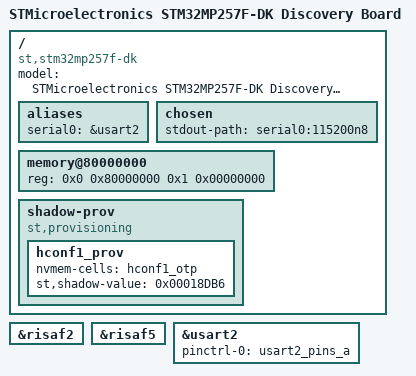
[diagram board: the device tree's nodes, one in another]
// SPDX-License-Identifier: (GPL-2.0-or-later OR BSD-3-Clause)
/*
 * Copyright (C) STMicroelectronics 2023 - All Rights Reserved
 * Author: Alexandre Torgue <alexandre.torgue@foss.st.com> for STMicroelectronics.
 */

/dts-v1/;

#include <dt-bindings/soc/stm32mp-provisioning.h>
#include "stm32mp257.dtsi"
#include "stm32mp25xf.dtsi"
#include "stm32mp25-pinctrl.dtsi"
#include "stm32mp25xxal-pinctrl.dtsi"

/ {
	model = "STMicroelectronics STM32MP257F-DK Discovery Board";
	compatible = "st,stm32mp257f-dk", "st,stm32mp257";

	aliases {
		serial0 = &usart2;
	};

	chosen {
		stdout-path = "serial0:115200n8";
	};

	memory@80000000 {
		device_type = "memory";
		reg = <0x0 0x80000000 0x1 0x00000000>;
	};

	shadow-prov {
		compatible = "st,provisioning";
		hconf1_prov {
			nvmem-cells = <&hconf1_otp>;
			st,shadow-value = <0x00018DB6>;
		};
	};
};

&risaf2 {
	status = "okay";
};

&risaf5 {
	status = "okay";
};

&usart2 {
	pinctrl-names = "default";
	pinctrl-0 = <&usart2_pins_a>;
	status = "okay";
};
